# MSP430F5529 register map
Vendor: msp430gen; File version: v0.4.0-10-gd4db4bc
Registers are 8-bit, read-write, reset 0x0 unless marked. A register's access mark holds for its fields unless they carry their own. Offsets are from the block's base; [hi:lo] are bit positions; {n}, {i} and the like mark numbered series.

## PORT_3_4
Base 0x00000220
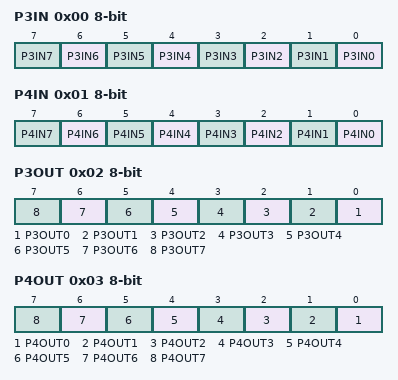
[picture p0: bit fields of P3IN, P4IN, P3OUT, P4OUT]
0x00 P3IN — Port 3 Input
  [n] P3IN{n} (n=0..7)
0x01 P4IN — Port 4 Input
  [n] P4IN{n} (n=0..7)
0x02 P3OUT — Port 3 Output
  [n] P3OUT{n} (n=0..7)
0x03 P4OUT — Port 4 Output
  [n] P4OUT{n} (n=0..7)
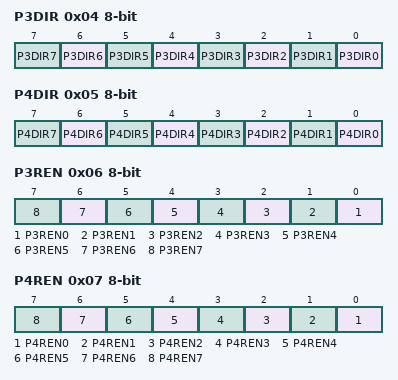
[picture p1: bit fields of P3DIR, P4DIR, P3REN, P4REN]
0x04 P3DIR — Port 3 Direction
  [n] P3DIR{n} (n=0..7)
0x05 P4DIR — Port 4 Direction
  [n] P4DIR{n} (n=0..7)
0x06 P3REN — Port 3 Resistor Enable
  [n] P3REN{n} (n=0..7)
0x07 P4REN — Port 4 Resistor Enable
  [n] P4REN{n} (n=0..7)
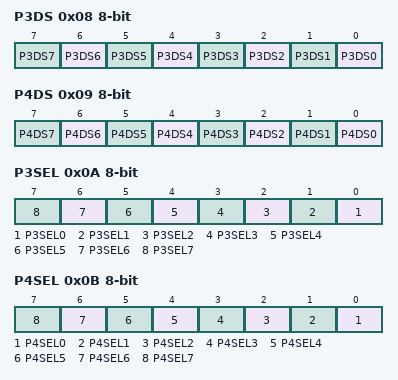
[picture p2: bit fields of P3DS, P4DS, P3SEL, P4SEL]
0x08 P3DS — Port 3 Drive Strenght
  [n] P3DS{n} (n=0..7)
0x09 P4DS — Port 4 Drive Strenght
  [n] P4DS{n} (n=0..7)
0x0A P3SEL — Port 3 Selection
  [n] P3SEL{n} (n=0..7)
0x0B P4SEL — Port 4 Selection
  [n] P4SEL{n} (n=0..7)

## PORT_5_6
Base 0x00000240
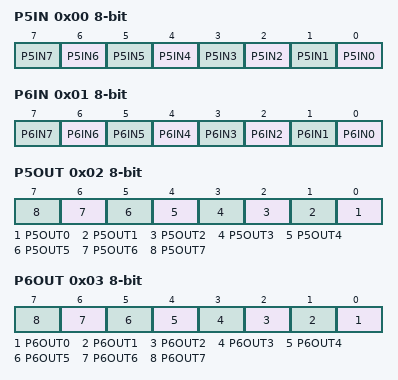
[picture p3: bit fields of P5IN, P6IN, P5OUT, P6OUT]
0x00 P5IN — Port 5 Input
  [n] P5IN{n} (n=0..7)
0x01 P6IN — Port 6 Input
  [n] P6IN{n} (n=0..7)
0x02 P5OUT — Port 5 Output
  [n] P5OUT{n} (n=0..7)
0x03 P6OUT — Port 6 Output
  [n] P6OUT{n} (n=0..7)
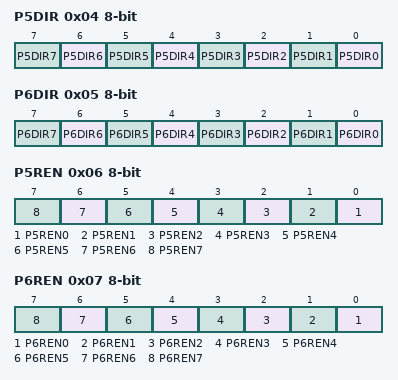
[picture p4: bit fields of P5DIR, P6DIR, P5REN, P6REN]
0x04 P5DIR — Port 5 Direction
  [n] P5DIR{n} (n=0..7)
0x05 P6DIR — Port 6 Direction
  [n] P6DIR{n} (n=0..7)
0x06 P5REN — Port 5 Resistor Enable
  [n] P5REN{n} (n=0..7)
0x07 P6REN — Port 6 Resistor Enable
  [n] P6REN{n} (n=0..7)
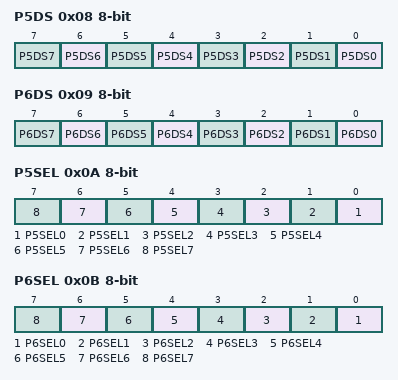
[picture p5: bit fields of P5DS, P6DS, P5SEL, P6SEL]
0x08 P5DS — Port 5 Drive Strenght
  [n] P5DS{n} (n=0..7)
0x09 P6DS — Port 6 Drive Strenght
  [n] P6DS{n} (n=0..7)
0x0A P5SEL — Port 5 Selection
  [n] P5SEL{n} (n=0..7)
0x0B P6SEL — Port 6 Selection
  [n] P6SEL{n} (n=0..7)

## PORT_7_8
Base 0x00000260
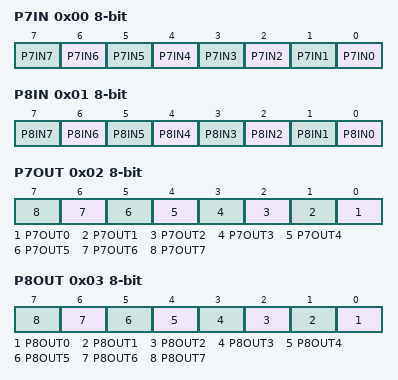
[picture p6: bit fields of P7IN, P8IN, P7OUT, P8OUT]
0x00 P7IN — Port 7 Input
  [n] P7IN{n} (n=0..7)
0x01 P8IN — Port 8 Input
  [n] P8IN{n} (n=0..7)
0x02 P7OUT — Port 7 Output
  [n] P7OUT{n} (n=0..7)
0x03 P8OUT — Port 8 Output
  [n] P8OUT{n} (n=0..7)
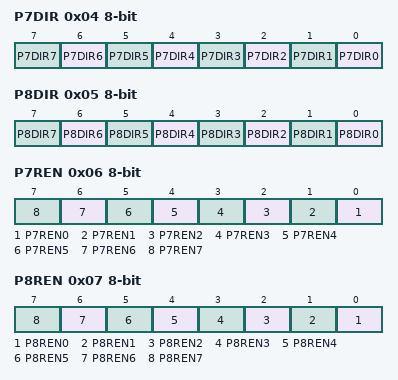
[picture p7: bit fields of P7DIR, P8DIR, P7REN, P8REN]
0x04 P7DIR — Port 7 Direction
  [n] P7DIR{n} (n=0..7)
0x05 P8DIR — Port 8 Direction
  [n] P8DIR{n} (n=0..7)
0x06 P7REN — Port 7 Resistor Enable
  [n] P7REN{n} (n=0..7)
0x07 P8REN — Port 8 Resistor Enable
  [n] P8REN{n} (n=0..7)
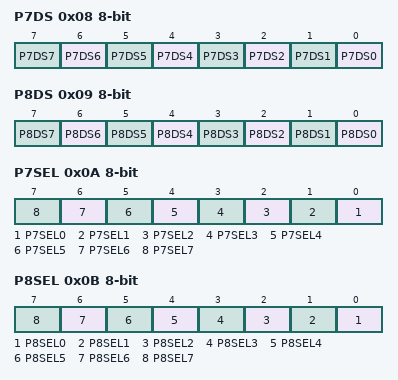
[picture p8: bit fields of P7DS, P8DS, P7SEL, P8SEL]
0x08 P7DS — Port 7 Drive Strenght
  [n] P7DS{n} (n=0..7)
0x09 P8DS — Port 8 Drive Strenght
  [n] P8DS{n} (n=0..7)
0x0A P7SEL — Port 7 Selection
  [n] P7SEL{n} (n=0..7)
0x0B P8SEL — Port 8 Selection
  [n] P8SEL{n} (n=0..7)

## USCI_A0_UART_MODE
Base 0x000005C0
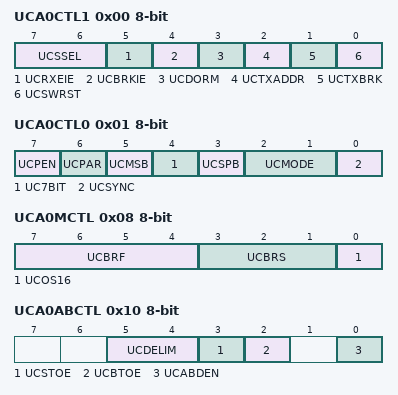
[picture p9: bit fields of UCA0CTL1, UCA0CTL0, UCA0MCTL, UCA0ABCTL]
0x00 UCA0CTL1 — USCI A0 Control Register 1
  [7:6] UCSSEL — USCI 0 Clock Source Select 1
    {v}=USCI 0 Clock Source: {v} (v=0..3)
  [5] UCRXEIE — RX Error interrupt enable
  [4] UCBRKIE — Break interrupt enable
  [3] UCDORM — Dormant (Sleep) Mode
  [2] UCTXADDR — Send next Data as Address
  [1] UCTXBRK — Send next Data as Break
  [0] UCSWRST — USCI Software Reset
0x01 UCA0CTL0 — USCI A0 Control Register 0
  [7] UCPEN — Async. Mode: Parity enable
  [6] UCPAR — Async. Mode: Parity 0:odd / 1:even
  [5] UCMSB — Async. Mode: MSB first 0:LSB / 1:MSB
  [4] UC7BIT — Async. Mode: Data Bits 0:8-bits / 1:7-bits
  [3] UCSPB — Async. Mode: Stop Bits 0:one / 1: two
  [2:1] UCMODE — Async. Mode: USCI Mode 1
    {v}=Sync. Mode: USCI Mode: {v} (v=0..3)
  [0] UCSYNC — Sync-Mode 0:UART-Mode / 1:SPI-Mode
0x06 UCA0BR0 — USCI A0 Baud Rate 0
  [7:0] UCA0BR0 — USCI A0 Baud Rate 0 register
0x07 UCA0BR1 — USCI A0 Baud Rate 1
  [7:0] UCA0BR1 — USCI A0 Baud Rate 1 register
0x08 UCA0MCTL — USCI A0 Modulation Control
  [7:4] UCBRF — USCI First Stage Modulation Select 3
    {v}=USCI First Stage Modulation: {v} (v=0..9); 10=USCI First Stage Modulation: A; 11=USCI First Stage Modulation: B; 12=USCI First Stage Modulation: C; 13=USCI First Stage Modulation: D; 14=USCI First Stage Modulation: E; 15=USCI First Stage Modulation: F
  [3:1] UCBRS — USCI Second Stage Modulation Select 2
    {v}=USCI Second Stage Modulation: {v} (v=0..7)
  [0] UCOS16 — USCI 16-times Oversampling enable
0x0A UCA0STAT — USCI A0 Status Register
  [7] UCLISTEN — USCI Listen mode
  [6] UCFE — USCI Frame Error Flag
  [5] UCOE — USCI Overrun Error Flag
  [4] UCPE — USCI Parity Error Flag
  [3] UCBRK — USCI Break received
  [2] UCRXERR — USCI RX Error Flag
  [1] UCADDR — USCI Address received Flag
  [1] UCIDLE — Idle line detected
  [0] UCBUSY — USCI Busy Flag
0x0C UCA0RXBUF — USCI A0 Receive Buffer
  [7:0] UCA0RXBUF — USCI A0 Receive Buffer register
0x0E UCA0TXBUF — USCI A0 Transmit Buffer
  [7:0] UCA0TXBUF — USCI A0 Transmit Buffer register
0x10 UCA0ABCTL — USCI A0 LIN Control
  [5:4] UCDELIM — Break Sync Delimiter 0
  [3] UCSTOE — Sync-Field Timeout error
  [2] UCBTOE — Break Timeout error
  [0] UCABDEN — Auto Baud Rate detect enable
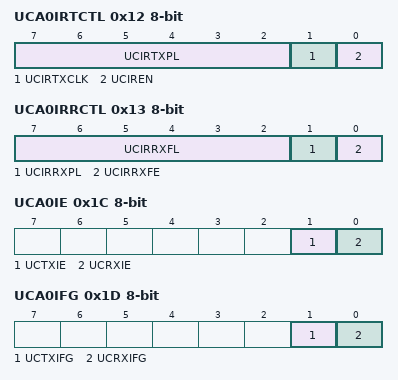
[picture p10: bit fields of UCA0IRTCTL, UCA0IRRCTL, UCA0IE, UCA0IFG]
0x12 UCA0IRTCTL — USCI A0 IrDA Transmit Control
  [7:2] UCIRTXPL — IRDA Transmit Pulse Length 0
  [1] UCIRTXCLK — IRDA Transmit Pulse Clock Select
  [0] UCIREN — IRDA Encoder/Decoder enable
0x13 UCA0IRRCTL — USCI A0 IrDA Receive Control
  [7:2] UCIRRXFL — IRDA Receive Filter Length 0
  [1] UCIRRXPL — IRDA Receive Input Polarity
  [0] UCIRRXFE — IRDA Receive Filter enable
0x1C UCA0IE — USCI A0 Interrupt Enable Register
  [1] UCTXIE — USCI Transmit Interrupt Enable
  [0] UCRXIE — USCI Receive Interrupt Enable
0x1D UCA0IFG — USCI A0 Interrupt Flags Register
  [1] UCTXIFG — USCI Transmit Interrupt Flag
  [0] UCRXIFG — USCI Receive Interrupt Flag
0x1E UCA0IV 16-bit — USCI A0 Interrupt Vector Register
